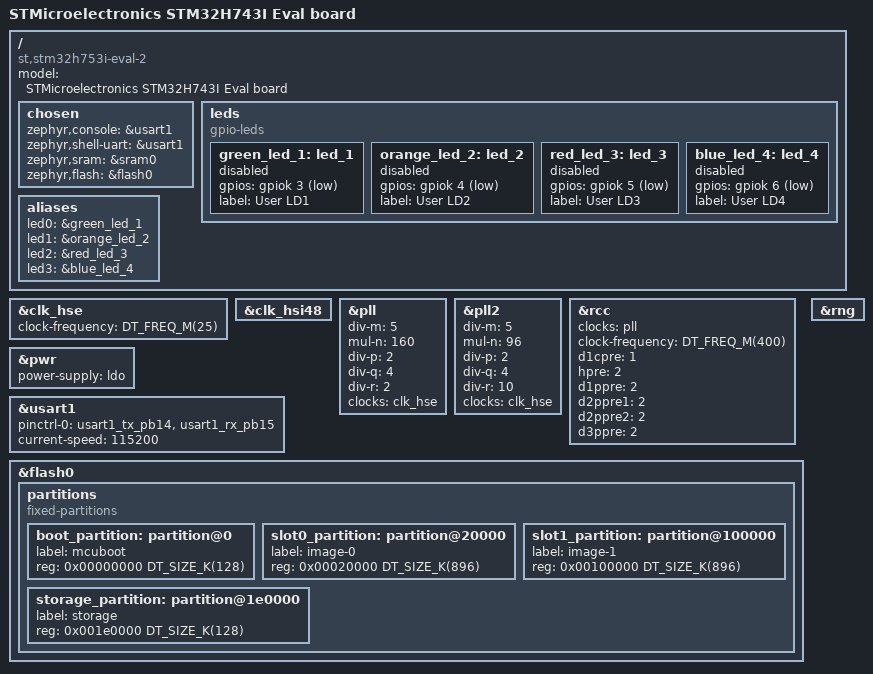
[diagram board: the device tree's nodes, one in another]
/*
 * Copyright (c) 2026 James Walmsley <james@fullfat-fs.co.uk>
 *
 * SPDX-License-Identifier: Apache-2
 */

/dts-v1/;
#include <st/h7/stm32h743Xi.dtsi>
#include <st/h7/stm32h743vitx-pinctrl.dtsi>

/ {
	model = "STMicroelectronics STM32H743I Eval board";
	compatible = "st,stm32h753i-eval-2";

	chosen {
		zephyr,console = &usart1;
		zephyr,shell-uart = &usart1;
		zephyr,sram = &sram0;
		zephyr,flash = &flash0;
	};

	leds {
		compatible = "gpio-leds";

		green_led_1: led_1 {
			gpios = <&gpiok 3 GPIO_ACTIVE_LOW>;
			label = "User LD1";
			status = "disabled";
		};

		orange_led_2: led_2 {
			gpios = <&gpiok 4 GPIO_ACTIVE_LOW>;
			label = "User LD2";
			status = "disabled";
		};

		red_led_3: led_3 {
			gpios = <&gpiok 5 GPIO_ACTIVE_LOW>;
			label = "User LD3";
			status = "disabled";
		};

		blue_led_4: led_4 {
			gpios = <&gpiok 6 GPIO_ACTIVE_LOW>;
			label = "User LD4";
			status = "disabled";
		};
	};

	aliases {
		led0 = &green_led_1;
		led1 = &orange_led_2;
		led2 = &red_led_3;
		led3 = &blue_led_4;
	};

};

&clk_hse {
	clock-frequency = <DT_FREQ_M(25)>;
	status = "okay";
};

&clk_hsi48 {
	status = "okay";
};

&pll {
	div-m = <5>;
	mul-n = <160>;
	div-p = <2>;
	div-q = <4>;
	div-r = <2>;
	clocks = <&clk_hse>;
	status = "okay";
};

&pll2 {
	div-m = <5>;
	mul-n = <96>;
	div-p = <2>;
	div-q = <4>;
	div-r = <10>;
	clocks = <&clk_hse>;  /* Assuming 25MHz HSE */
	status = "okay";
};

&rcc {
	clocks = <&pll>;
	clock-frequency = <DT_FREQ_M(400)>;
	d1cpre = <1>;
	hpre = <2>;
	d1ppre = <2>;
	d2ppre1 = <2>;
	d2ppre2 = <2>;
	d3ppre = <2>;
};

&pwr {
	power-supply = "ldo";
};

&usart1 {
	status = "okay";
	pinctrl-0 = <&usart1_tx_pb14 &usart1_rx_pb15>;
	pinctrl-names = "default";
	current-speed = <115200>;
};

&flash0 {
	partitions {
		compatible = "fixed-partitions";
		#address-cells = <1>;
		#size-cells = <1>;

		boot_partition: partition@0 {
			label = "mcuboot";
			reg = <0x00000000 DT_SIZE_K(128)>;
		};

		slot0_partition: partition@20000 {
			label = "image-0";
			reg = <0x00020000 DT_SIZE_K(896)>;
		};

		slot1_partition: partition@100000 {
			label = "image-1";
			reg = <0x00100000 DT_SIZE_K(896)>;
		};

		storage_partition: partition@1e0000 {
			label = "storage";
			reg = <0x001e0000 DT_SIZE_K(128)>;
		};
	};
};

/* &mac { */
/* 	status = "okay"; */
/* 	pinctrl-0 = <&eth_ref_clk_pa1 */
/* 		     &eth_crs_dv_pa7 */
/* 		     &eth_rxd0_pc4 */
/* 		     &eth_rxd1_pc5 */
/* 		     &eth_tx_en_pg11 */
/* 		     &eth_txd0_pg13 */
/* 		     &eth_txd1_pg12>; */
/* 	pinctrl-names = "default"; */
/* 	phy-connection-type = "rmii"; */
/* 	phy-handle = <&eth_phy>; */
/* }; */
/**/
/* &mdio { */
/* 	status = "okay"; */
/* 	pinctrl-0 = <&eth_mdio_pa2 &eth_mdc_pc1>; */
/* 	pinctrl-names = "default"; */
/**/
/* 	eth_phy: ethernet-phy@0 { */
/* 		compatible = "ethernet-phy"; */
/* 		reg = <0x00>; */
/* 	}; */
/* }; */
/**/
&rng {
	status = "okay";
};
